# RZT2ME register map
Vendor: Renesas Electronics Corporation; Series: RZT; File version: 1.00.00
CPU: other r0p0, little endian, MPU, no FPU, VTOR, 4 interrupt priority bits, 624 interrupts
Registers are 32-bit, read-write, reset 0x0 unless marked. A register's access mark holds for its fields unless they carry their own. Offsets are from the block's base; [hi:lo] are bit positions; {n}, {i} and the like mark numbered series; 'fields as' and 'values as' point back to an identical list.

## ELC — Evnet Link Controller
Base 0x80090010
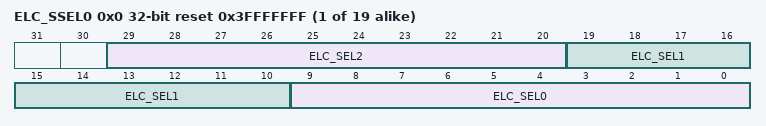
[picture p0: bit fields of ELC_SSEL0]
{0x0+4i} ELC_SSEL{i} (i=0..18) reset 0x3FFFFFFF — ELC Event Source Select Register {i}
  [29:20] ELC_SEL2 — Set the number for ELC event source to be linked to the ELC destination.
  [19:10] ELC_SEL1 — Set the number for ELC event source to be linked to the ELC destination.
  [9:0] ELC_SEL0 — Set the number for ELC event source to be linked to the ELC destination.

## DMA — DMAC Configuration
Base 0x80090060
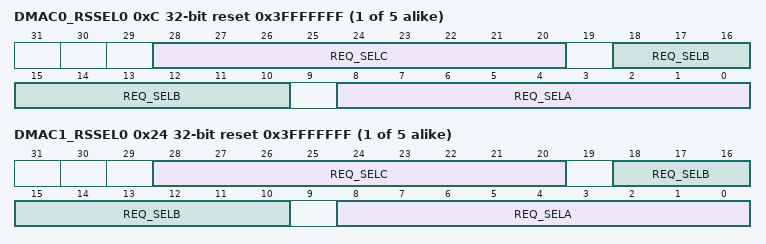
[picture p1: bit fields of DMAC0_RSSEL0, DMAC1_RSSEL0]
{0xC+4i} DMAC0_RSSEL{i} (i=0..4) reset 0x3FFFFFFF — DMAC Unit 0 Resource Select Register {i}
  [28:20] REQ_SELC — DMA Resource Select for Channel n + 2
  [18:10] REQ_SELB — DMA Resource Select for Channel n + 1
  [8:0] REQ_SELA — DMA Resource Select for Channel n
0x20 DMAC0_RSSEL5 reset 0x3FF — DMAC Unit 0 Resource Select Register 5
  [8:0] REQ_SELA — DMA Resource Select for Channel n
{0x24+4i} DMAC1_RSSEL{i} (i=0..4) reset 0x3FFFFFFF — DMAC Unit 1 Resource Select Register {i}
  fields as DMAC0_RSSEL0
0x38 DMAC1_RSSEL5 reset 0x3FF — DMAC Unit 1 Resource Select Register 5
  [8:0] REQ_SELA — DMA Resource Select for Channel n

## ESC_INI — Initial Configuration 1 for EtherCAT Slave Controller
Base 0x80110200
0x00 ECATOFFADR — EtherCAT PHY Offset Address Setting Register
  [4:0] OADD — PHY Offset Address Setting
0x04 ECATOPMOD — EtherCAT Operation Mode Register
  [0] EEPROMSIZE — EEPROM Memory Size Specification
    0=16 Kbits or less; 1=32 Kbits to 4 Mbits
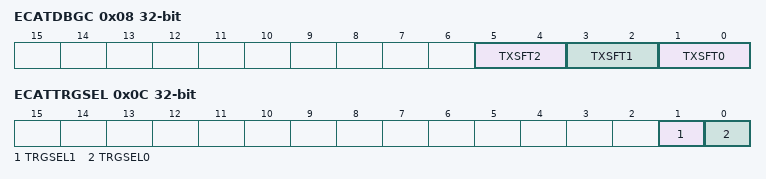
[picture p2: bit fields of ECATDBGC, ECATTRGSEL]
0x08 ECATDBGC — EtherCAT Debug Control Register
  [all] fields
    0=0 ns; 1=10 ns; 2=20 ns; 3=30 ns
  [5:4] TXSFT2 — Set the delay time for ETH2_TXEN and ETH2_TXDn of the EtherCAT
  [3:2] TXSFT1 — Set the delay time for ETH1_TXEN and ETH1_TXDn of the EtherCAT
  [1:0] TXSFT0 — Set the delay time for ETH0_TXEN and ETH0_TXDn of the EtherCAT
0x0C ECATTRGSEL — EtherCAT DC Latch Trigger Select Register
  [1] TRGSEL1 — Select DC Latch Trigger 1 for ESC
    0=Select LATCH1 input from ELC; 1=Select LATCH1 input from external
  [0] TRGSEL0 — Select DC Latch Trigger 0 for ESC
    0=Select LATCH0 input from ELC; 1=Select LATCH0 input from external

## ETHSW_PTP — Ethernet Switch for PTP
Base 0x80110400
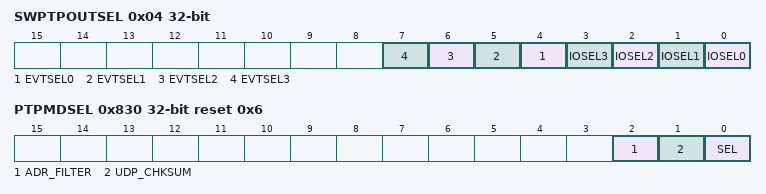
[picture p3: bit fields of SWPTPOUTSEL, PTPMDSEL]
0x04 SWPTPOUTSEL — ETHSW_PTPOUT Select Register
  [n+4] EVTSEL{n} (n=0..3) — Select the source of the ETHSW_PTPOUT{n} event for GIC, DMAC, and ELC
    0=Pulse generator {n} output; 1=TDMA_GPIO[{n+4}] output
  [n] IOSEL{n} (n=0..3) — Select the source of the ETHSW_PTPOUT{n} output signal
    0=Pulse generator {n} output; 1=TDMA_GPIO[{n+4}] output
{0x400+0x100*i} SWTMEN{i} (i=0..3) — PTP Timer Pulse Output Enable {i} Register
  [0] OUTEN — Enable ETHSW_PTPOUTn Signal Output
    0=Disabled; 1=Enabled
{0x404+0x100*i} SWTMSTSEC{i} (i=0..3) — PTP Timer Pulse Start Second {i} Register
  [31:0] STSEC
{0x408+0x100*i} SWTMSTNS{i} (i=0..3) — PTP Timer Pulse Start Nanosecond {i} Register
  [31:0] STNS — Start Time by Nanosecond
{0x40C+0x100*i} SWTMPSEC{i} (i=0..3) — PTP Timer Pulse Period Second {i} Register
  [31:0] PSEC
{0x410+0x100*i} SWTMPNS{i} (i=0..3) reset 0x3B9ACA00 — PTP Timer Pulse Period Nanosecond {i} Register
  [31:0] PNS — Period by Nanosecond
{0x414+0x100*i} SWTMWTH{i} (i=0..3) reset 0x3 — PTP Timer Pulse Width {i} Register
  [15:0] WIDTH — Set the Pulse Width of ETHSW_PTPOUTn in the cycle number of ts_clk (8 ns).
{0x418+0x100*i} SWTMMAXP{i} (i=0..3) reset 0x3B9ACA00 — PTP Timer Pulse Max Nanosecond {i} Register
  [31:0] MAXP — Sets the boundary value in nanoseconds to carry from the nanosecond field to the second field. The same value as ATIME_EVT_PERIOD register must be set.
{0x41C+0x100*i} SWTMLATSEC{i} (i=0..3) — PTP Timer Pulse Latch Second {i} Register
  [31:0] LATSEC
{0x420+0x100*i} SWTMLATNS{i} (i=0..3) — PTP Timer Pulse Latch Nanosecond {i} Register
  [31:0] LATNS
0x830 PTPMDSEL reset 0x6 — PTP Mode Selection Register
  [2] ADR_FILTER — Selection of IPv4 address filtering
    0=IPv4 Destination Address Filtering OFF mode. Disabled filtering by IPV4_DEST_ADR register.; 1=IPv4 Destination Address Filtering ON mode. Enabled filtering by IPV4_DEST_ADR register.
  [1] UDP_CHKSUM — Selection of UDP checksum processing
    0=Zero UDP checksum mode; 1=Incremental UDP checksum mode
  [0] SEL — PTP function select
    0=Processing of only PTP over Layer 2; 1=Sequential Processing of PTP over Layer 2 and PTP over UDP/IPv4. The UDP_CHKSUM and ADR_FILTER bits are valid when SEL = 1.
0x834 IPV4_DEST_ADR reset 0x810100E0 — IPv4 Header Destination Address Register
  [31:0] DESTADR — DESTADR[7:0]: Destination address of IPv4 header and the first byte of frame.
0x838 UDP_DEST_PORTNUM reset 0x3F01 — UDP Header Destination Port Number Register
  [15:0] PORTNUM — PORTNUM[7:0]: Destination port number of UDP header and the first byte of frame
